# gcfr_me17 register map
Registers are read-write, no defined reset value unless marked. A register's access mark holds for its fields unless they carry their own. Offsets are from the block's base; lines under a group give offsets from that group; [hi:lo] are bit positions; {n}, {i} and the like mark numbered series; 'fields as' and 'values as' point back to an identical list; <NAME> marks a mode.

## Memory map
0x40005800 GCFR size 0x400 — Global Control Function Register.

## GCFR — Global Control Function Register.
Base 0x40005800
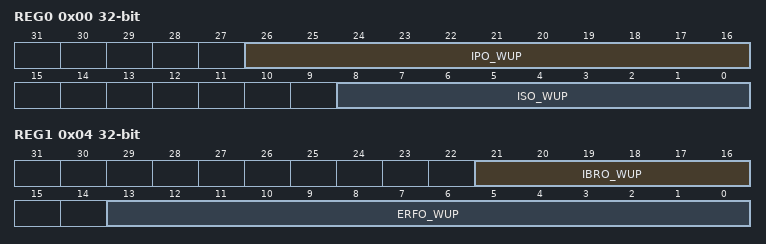
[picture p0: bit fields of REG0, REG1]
0x00 REG0 — Register 0.
  [26:16] IPO_WUP — IPO Warm Up Value.
  [8:0] ISO_WUP — ISO Warm Up Value.
0x04 REG1 — Register 1.
  [21:16] IBRO_WUP — IBRO Warm Up Value.
  [13:0] ERFO_WUP — ERFO Warm Up Value.
